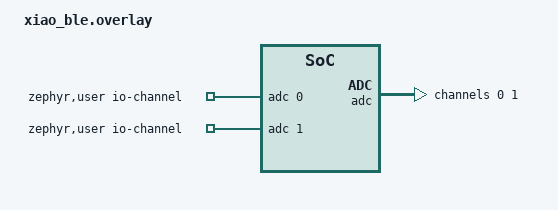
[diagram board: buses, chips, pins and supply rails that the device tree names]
#include <zephyr/dt-bindings/adc/adc.h>
#include <zephyr/dt-bindings/adc/nrf-saadc.h>

/ {
    zephyr,user {
        io-channels = <&adc 0>, <&adc 1>;
    };
};

&adc {
    #address-cells = <1>;
    #size-cells = <0>;
    status = "okay";

    channel@0 {
        reg = <0>;
        zephyr,gain = "ADC_GAIN_1_4";
        zephyr,reference = "ADC_REF_VDD_1_4";
        zephyr,acquisition-time = <ADC_ACQ_TIME_DEFAULT>;
        zephyr,input-positive = <NRF_SAADC_AIN0>;
    };

    channel@1 {
        reg = <1>;
        zephyr,gain = "ADC_GAIN_1_4";
        zephyr,reference = "ADC_REF_VDD_1_4";
        zephyr,acquisition-time = <ADC_ACQ_TIME_DEFAULT>;
        zephyr,input-positive = <NRF_SAADC_AIN1>;
    };
};
